# M066 register map
File version: 0.1
Registers are 32-bit, read-write, reset 0x0 unless marked. A register's access mark holds for its fields unless they carry their own. Offsets are from the block's base; [hi:lo] are bit positions.

## TD0 — Timer D (Unit0)
Base 0x40058000
0x00 RUN wo — Timer Run Register (Unit0)
  [0] TDRUN
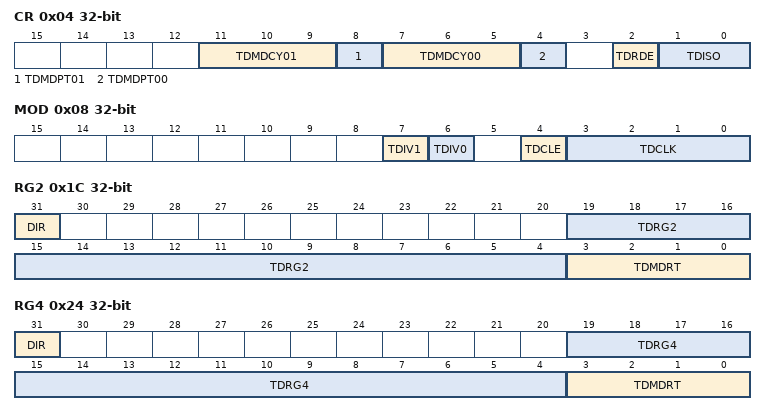
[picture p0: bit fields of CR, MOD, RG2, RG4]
0x04 CR — Timer Control Register (Unit0)
  [11:9] TDMDCY01, [8] TDMDPT01, [7:5] TDMDCY00, [4] TDMDPT00, [2] TDRDE, [1:0] TDISO
0x08 MOD — Timer Mode Register (Unit0)
  [7] TDIV1, [6] TDIV0, [4] TDCLE, [3:0] TDCLK
0x0C DMA — DMA Request Enable Register (Unit0)
  [0] DMAEN
0x14 RG0 — Timer Register0 (Unit0)
  [15:0] TDRG0
0x18 RG1 — Timer Register1 (Unit0)
  [15:0] TDRG1
0x1C RG2 — Timer Register2 (Unit0)
  [31] DIR, [19:4] TDRG2, [3:0] TDMDRT
0x20 RG3 — Timer Register3 (Unit0)
  [15:0] TDRG3
0x24 RG4 — Timer Register4 (Unit0)
  [31] DIR, [19:4] TDRG4, [3:0] TDMDRT
0x28 RG5 — Timer Register5 (Unit0)
  [16:1] TDRG5
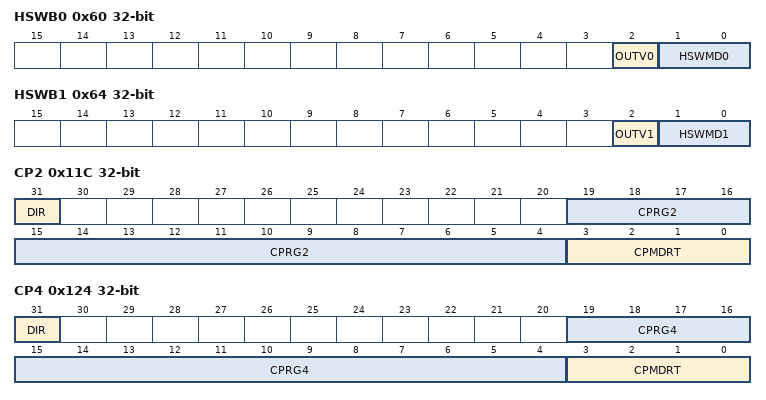
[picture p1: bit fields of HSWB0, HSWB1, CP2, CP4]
0x60 HSWB0 — H-SW Control Circuit Register Buffer0 (Unit0)
  [2] OUTV0, [1:0] HSWMD0
0x64 HSWB1 — H-SW Control Circuit Register Buffer1 (Unit0)
  [2] OUTV1, [1:0] HSWMD1
0x114 CP0 ro — Compare Register0 (Unit0)
  [15:0] CPRG0
0x118 CP1 ro — Compare Register1 (Unit0)
  [15:0] CPRG1
0x11C CP2 ro — Compare Register2 (Unit0)
  [31] DIR, [19:4] CPRG2, [3:0] CPMDRT
0x120 CP3 ro — Compare Register3 (Unit0)
  [15:0] CPRG3
0x124 CP4 ro — Compare Register4 (Unit0)
  [31] DIR, [19:4] CPRG4, [3:0] CPMDRT
0x128 CP5 ro — Compare Register5 (Unit0)
  [15:0] CPRG5
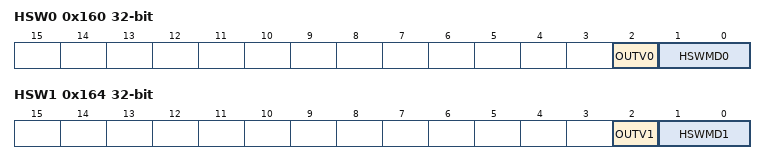
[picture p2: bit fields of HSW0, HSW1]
0x160 HSW0 ro — H-SW Control Circuit Register (Unit0)
  [2] OUTV0, [1:0] HSWMD0
0x164 HSW1 ro — H-SW Control Circuit Register (Unit0)
  [2] OUTV1, [1:0] HSWMD1

## TD — Timer D common
Base 0x40058040
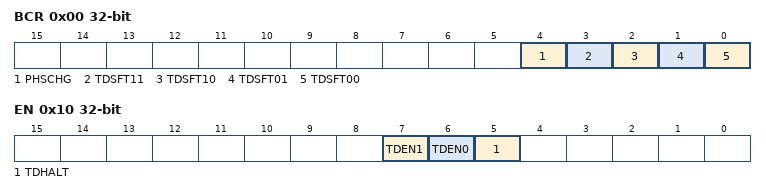
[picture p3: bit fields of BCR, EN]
0x00 BCR — Update Flag Setting Register
  [4] PHSCHG, [3] TDSFT11, [2] TDSFT10, [1] TDSFT01, [0] TDSFT00
0x10 EN — Timer Enable Register
  [7] TDEN1, [6] TDEN0, [5] TDHALT
0x14 CONF — Timer Configuration Register
  [2:0] TMRDMOD

## TD1 — Timer D (Unit1)
Base 0x4005802C
0x00 RG0 — Timer Register0 (Unit1)
  [15:0] TDRG0
0x04 RG1 — Timer Register1 (Unit1)
  [15:0] TDRG1
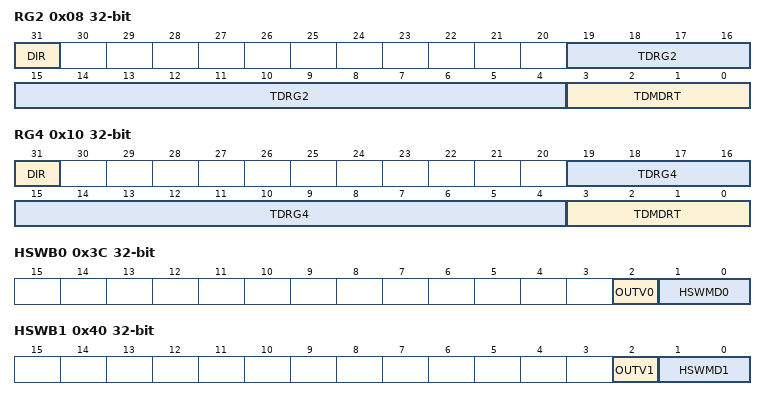
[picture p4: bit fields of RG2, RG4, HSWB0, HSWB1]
0x08 RG2 — Timer Register2 (Unit1)
  [31] DIR, [19:4] TDRG2, [3:0] TDMDRT
0x0C RG3 — Timer Register3 (Unit1)
  [15:0] TDRG3
0x10 RG4 — Timer Register4 (Unit1)
  [31] DIR, [19:4] TDRG4, [3:0] TDMDRT
0x3C HSWB0 — H-SW Control Circuit Register Buffer0 (Unit1)
  [2] OUTV0, [1:0] HSWMD0
0x40 HSWB1 — H-SW Control Circuit Register Buffer1 (Unit1)
  [2] OUTV1, [1:0] HSWMD1
0xD4 RUN wo — Timer Run Register (Unit1)
  [0] TDRUN
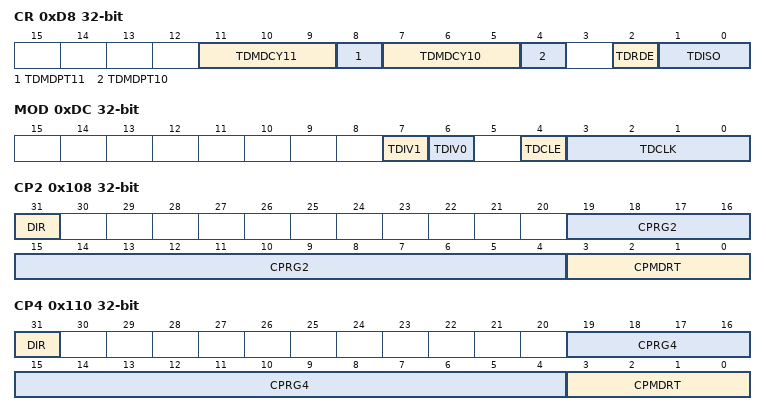
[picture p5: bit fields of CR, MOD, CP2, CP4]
0xD8 CR — Timer Control Register (Unit1)
  [11:9] TDMDCY11, [8] TDMDPT11, [7:5] TDMDCY10, [4] TDMDPT10, [2] TDRDE, [1:0] TDISO
0xDC MOD — Timer Mode Register (Unit1)
  [7] TDIV1, [6] TDIV0, [4] TDCLE, [3:0] TDCLK
0xE0 DMA — DMA Request Enable Register (Unit1)
  [0] DMAEN
0x100 CP0 ro — Compare Register0 (Unit1)
  [15:0] CPRG0
0x104 CP1 ro — Compare Register1 (Unit1)
  [15:0] CPRG1
0x108 CP2 ro — Compare Register2 (Unit1)
  [31] DIR, [19:4] CPRG2, [3:0] CPMDRT
0x10C CP3 ro — Compare Register3 (Unit1)
  [15:0] CPRG3
0x110 CP4 ro — Compare Register4 (Unit1)
  [31] DIR, [19:4] CPRG4, [3:0] CPMDRT
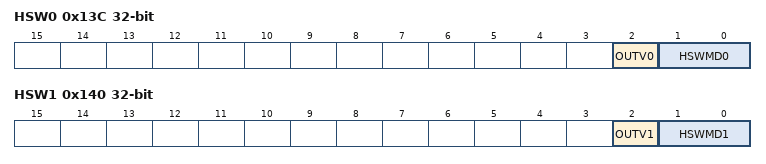
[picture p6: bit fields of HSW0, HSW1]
0x13C HSW0 ro — H-SW Control Circuit Register (Unit1)
  [2] OUTV0, [1:0] HSWMD0
0x140 HSW1 ro — H-SW Control Circuit Register (Unit1)
  [2] OUTV1, [1:0] HSWMD1

## T16A0 — 16-bit TimerA
Base 0x4008D000
Same registers: T16A1 0x4008E000
0x00 EN — Enable Register
  [1] HALT
0x04 RUN
  [0] RUN
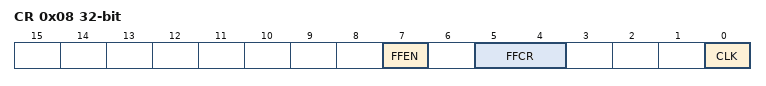
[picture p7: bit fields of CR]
0x08 CR — Control Register
  [7] FFEN, [5:4] FFCR wo, [0] CLK
0x0C RG — Timer Register
  [15:0] RG
0x10 CP ro — Capture Register
  [15:0] CP

## TSPI — Serial Interface (TSPI)
Base 0x40098000
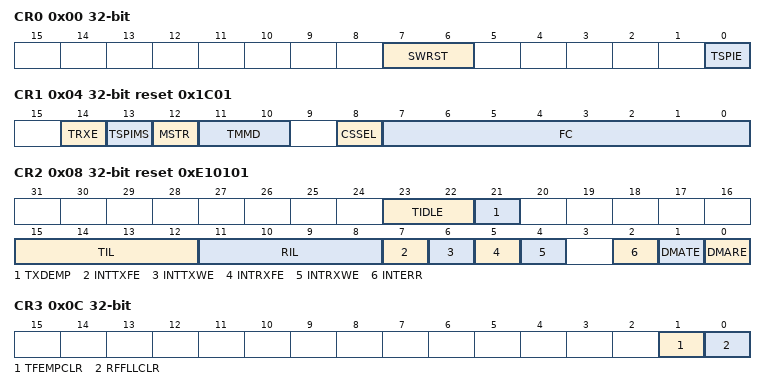
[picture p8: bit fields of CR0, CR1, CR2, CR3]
0x00 CR0 — TSPI Control Register 0
  [7:6] SWRST wo, [0] TSPIE
0x04 CR1 reset 0x1C01 — TSPI Control Register 1
  [14] TRXE, [13] TSPIMS, [12] MSTR, [11:10] TMMD, [8] CSSEL, [7:0] FC
0x08 CR2 reset 0xE10101 — TSPI Control Register 2
  [23:22] TIDLE, [21] TXDEMP, [15:12] TIL, [11:8] RIL, [7] INTTXFE, [6] INTTXWE, [5] INTRXFE, [4] INTRXWE, [2] INTERR, [1] DMATE, [0] DMARE
0x0C CR3 — TSPI Control Register 3
  [1] TFEMPCLR wo, [0] RFFLLCLR wo
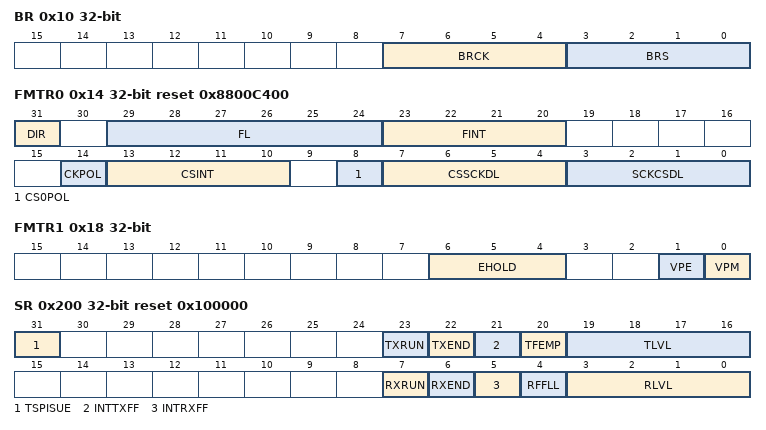
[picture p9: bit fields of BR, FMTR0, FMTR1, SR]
0x10 BR — TSPI Baud Rate Generator Control Register
  [7:4] BRCK, [3:0] BRS
0x14 FMTR0 reset 0x8800C400 — TSPI Format Control Register 0
  [31] DIR, [29:24] FL, [23:20] FINT, [14] CKPOL, [13:10] CSINT, [8] CS0POL, [7:4] CSSCKDL, [3:0] SCKCSDL
0x18 FMTR1 — TSPI Format Control Register 1
  [6:4] EHOLD, [1] VPE, [0] VPM
0x100 DR — TSPI Data Register
  [31:0] TSPIDR
0x200 SR reset 0x100000 — TSPI Status Register
  [31] TSPISUE ro, [23] TXRUN ro, [22] TXEND, [21] INTTXFF, [20] TFEMP ro, [19:16] TLVL ro, [7] RXRUN ro, [6] RXEND, [5] INTRXFF, [4] RFFLL ro, [3:0] RLVL ro
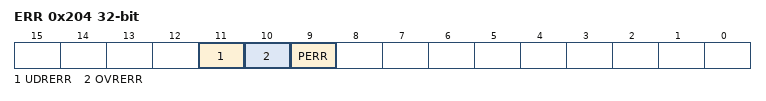
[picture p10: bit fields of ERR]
0x204 ERR — TSPI Parity Error Flag Register
  [11] UDRERR, [10] OVRERR, [9] PERR
